VERSION ""

NS_ :

BS_:
BU_: TEENSY1 TEENSY2 TEENSY3 TEENSY4 HOST
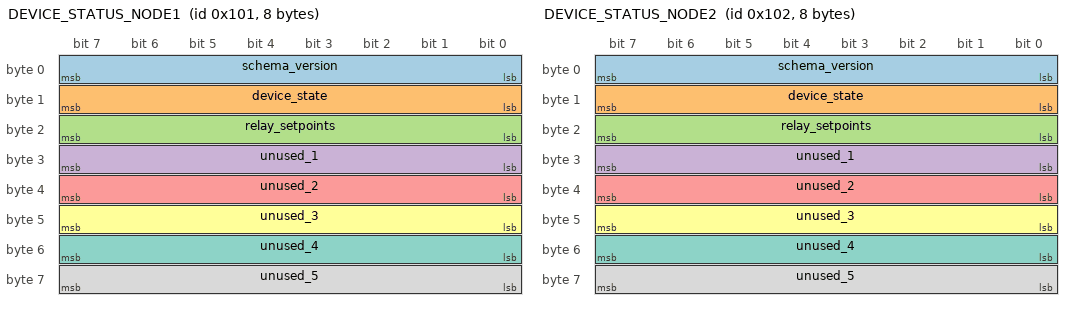
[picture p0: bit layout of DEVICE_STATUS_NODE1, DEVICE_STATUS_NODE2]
BO_ 257 DEVICE_STATUS_NODE1: 8 TEENSY1
   SG_ schema_version : 0|8@1+ (1,0) [0|255] "" HOST
   SG_ device_state : 8|8@1+ (1,0) [0|2] "" HOST
   SG_ relay_setpoints : 16|8@1+ (1,0) [0|255] "" HOST
   SG_ unused_1 : 24|8@1+ (1,0) [0|255] "" HOST
   SG_ unused_2 : 32|8@1+ (1,0) [0|255] "" HOST
   SG_ unused_3 : 40|8@1+ (1,0) [0|255] "" HOST
   SG_ unused_4 : 48|8@1+ (1,0) [0|255] "" HOST
   SG_ unused_5 : 56|8@1+ (1,0) [0|255] "" HOST

BO_ 258 DEVICE_STATUS_NODE2: 8 TEENSY2
   SG_ schema_version : 0|8@1+ (1,0) [0|255] "" HOST
   SG_ device_state : 8|8@1+ (1,0) [0|2] "" HOST
   SG_ relay_setpoints : 16|8@1+ (1,0) [0|255] "" HOST
   SG_ unused_1 : 24|8@1+ (1,0) [0|255] "" HOST
   SG_ unused_2 : 32|8@1+ (1,0) [0|255] "" HOST
   SG_ unused_3 : 40|8@1+ (1,0) [0|255] "" HOST
   SG_ unused_4 : 48|8@1+ (1,0) [0|255] "" HOST
   SG_ unused_5 : 56|8@1+ (1,0) [0|255] "" HOST

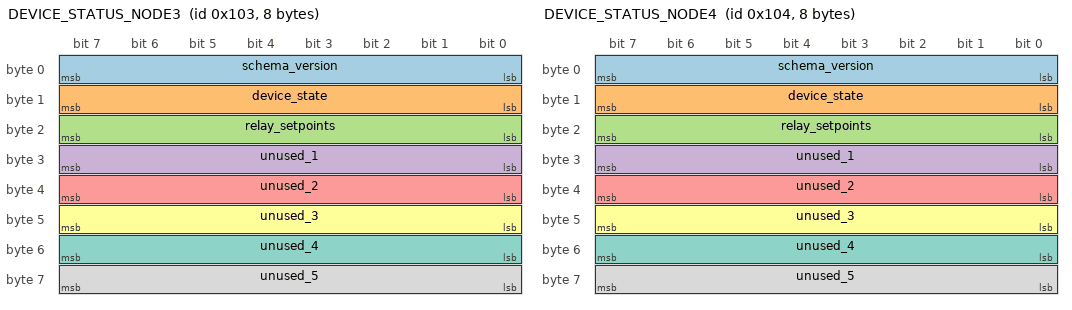
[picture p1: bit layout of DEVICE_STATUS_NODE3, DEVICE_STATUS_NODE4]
BO_ 259 DEVICE_STATUS_NODE3: 8 TEENSY3
   SG_ schema_version : 0|8@1+ (1,0) [0|255] "" HOST
   SG_ device_state : 8|8@1+ (1,0) [0|2] "" HOST
   SG_ relay_setpoints : 16|8@1+ (1,0) [0|255] "" HOST
   SG_ unused_1 : 24|8@1+ (1,0) [0|255] "" HOST
   SG_ unused_2 : 32|8@1+ (1,0) [0|255] "" HOST
   SG_ unused_3 : 40|8@1+ (1,0) [0|255] "" HOST
   SG_ unused_4 : 48|8@1+ (1,0) [0|255] "" HOST
   SG_ unused_5 : 56|8@1+ (1,0) [0|255] "" HOST

BO_ 260 DEVICE_STATUS_NODE4: 8 TEENSY4
   SG_ schema_version : 0|8@1+ (1,0) [0|255] "" HOST
   SG_ device_state : 8|8@1+ (1,0) [0|2] "" HOST
   SG_ relay_setpoints : 16|8@1+ (1,0) [0|255] "" Vector__XXX
   SG_ unused_1 : 24|8@1+ (1,0) [0|255] "" HOST
   SG_ unused_2 : 32|8@1+ (1,0) [0|255] "" HOST
   SG_ unused_3 : 40|8@1+ (1,0) [0|255] "" HOST
   SG_ unused_4 : 48|8@1+ (1,0) [0|255] "" HOST
   SG_ unused_5 : 56|8@1+ (1,0) [0|255] "" HOST

BA_DEF_ BO_ "GenMsgCycleTime" INT 0 65535;
BA_DEF_ BO_ "GenMsgBackgroundColor" STRING ;
BA_DEF_ BO_ "GenMsgForegroundColor" STRING ;
BA_ "GenMsgCycleTime" BO_ 257 1000;
BA_ "GenMsgCycleTime" BO_ 258 1000;
BA_ "GenMsgCycleTime" BO_ 259 1000;
BA_ "GenMsgCycleTime" BO_ 260 1000;
BA_DEF_DEF_ "GenMsgBackgroundColor" "#ffffff";
BA_DEF_DEF_ "GenMsgForegroundColor" "#000000";
